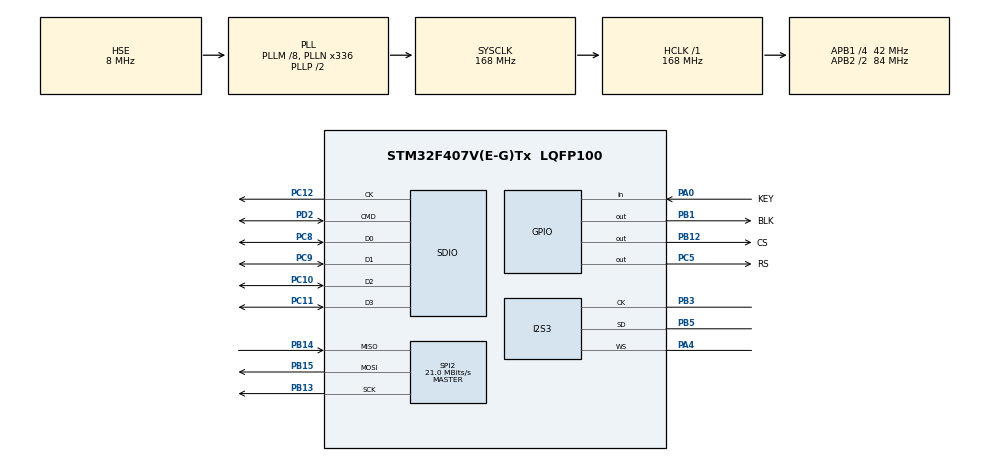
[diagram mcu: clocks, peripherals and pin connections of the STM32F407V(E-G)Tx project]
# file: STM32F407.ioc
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Dma.Request0=SDIO_RX
Dma.Request1=SDIO_TX
Dma.Request2=SPI2_RX
Dma.Request3=SPI2_TX
Dma.Request4=SPI3_TX
Dma.SDIO_RX.0.Direction=DMA_PERIPH_TO_MEMORY
Dma.SDIO_RX.0.FIFOMode=DMA_FIFOMODE_ENABLE
Dma.SDIO_RX.0.FIFOThreshold=DMA_FIFO_THRESHOLD_FULL
Dma.SDIO_RX.0.Instance=DMA2_Stream3
Dma.SDIO_RX.0.MemBurst=DMA_MBURST_INC4
Dma.SDIO_RX.0.MemDataAlignment=DMA_MDATAALIGN_WORD
Dma.SDIO_RX.0.MemInc=DMA_MINC_ENABLE
Dma.SDIO_RX.0.Mode=DMA_PFCTRL
Dma.SDIO_RX.0.PeriphBurst=DMA_PBURST_INC4
Dma.SDIO_RX.0.PeriphDataAlignment=DMA_PDATAALIGN_WORD
Dma.SDIO_RX.0.PeriphInc=DMA_PINC_DISABLE
Dma.SDIO_RX.0.Priority=DMA_PRIORITY_LOW
Dma.SDIO_TX.1.Direction=DMA_MEMORY_TO_PERIPH
Dma.SDIO_TX.1.FIFOMode=DMA_FIFOMODE_ENABLE
Dma.SDIO_TX.1.FIFOThreshold=DMA_FIFO_THRESHOLD_FULL
Dma.SDIO_TX.1.Instance=DMA2_Stream6
Dma.SDIO_TX.1.MemBurst=DMA_MBURST_INC4
Dma.SDIO_TX.1.MemDataAlignment=DMA_MDATAALIGN_WORD
Dma.SDIO_TX.1.MemInc=DMA_MINC_ENABLE
Dma.SDIO_TX.1.Mode=DMA_PFCTRL
Dma.SDIO_TX.1.PeriphBurst=DMA_PBURST_INC4
Dma.SDIO_TX.1.PeriphDataAlignment=DMA_PDATAALIGN_WORD
Dma.SDIO_TX.1.PeriphInc=DMA_PINC_DISABLE
Dma.SDIO_TX.1.Priority=DMA_PRIORITY_LOW
Dma.SPI2_RX.2.Direction=DMA_PERIPH_TO_MEMORY
Dma.SPI2_RX.2.FIFOMode=DMA_FIFOMODE_DISABLE
Dma.SPI2_RX.2.Instance=DMA1_Stream3
Dma.SPI2_RX.2.MemDataAlignment=DMA_MDATAALIGN_BYTE
Dma.SPI2_RX.2.MemInc=DMA_MINC_ENABLE
Dma.SPI2_RX.2.Mode=DMA_NORMAL
Dma.SPI2_RX.2.PeriphDataAlignment=DMA_PDATAALIGN_BYTE
Dma.SPI2_RX.2.PeriphInc=DMA_PINC_DISABLE
Dma.SPI2_RX.2.Priority=DMA_PRIORITY_LOW
Dma.SPI2_TX.3.Direction=DMA_MEMORY_TO_PERIPH
Dma.SPI2_TX.3.FIFOMode=DMA_FIFOMODE_DISABLE
Dma.SPI2_TX.3.Instance=DMA1_Stream4
Dma.SPI2_TX.3.MemDataAlignment=DMA_MDATAALIGN_BYTE
Dma.SPI2_TX.3.MemInc=DMA_MINC_ENABLE
Dma.SPI2_TX.3.Mode=DMA_NORMAL
Dma.SPI2_TX.3.PeriphDataAlignment=DMA_PDATAALIGN_BYTE
Dma.SPI2_TX.3.PeriphInc=DMA_PINC_DISABLE
Dma.SPI2_TX.3.Priority=DMA_PRIORITY_LOW
Dma.SPI3_TX.4.Direction=DMA_MEMORY_TO_PERIPH
Dma.SPI3_TX.4.FIFOMode=DMA_FIFOMODE_DISABLE
Dma.SPI3_TX.4.Instance=DMA1_Stream5
Dma.SPI3_TX.4.MemDataAlignment=DMA_MDATAALIGN_BYTE
Dma.SPI3_TX.4.MemInc=DMA_MINC_ENABLE
Dma.SPI3_TX.4.Mode=DMA_NORMAL
Dma.SPI3_TX.4.PeriphDataAlignment=DMA_PDATAALIGN_BYTE
Dma.SPI3_TX.4.PeriphInc=DMA_PINC_DISABLE
Dma.SPI3_TX.4.Priority=DMA_PRIORITY_LOW
FREERTOS.Tasks01=defaultTask,24,512,StartDefaultTask,Default,NULL,Dynamic,NULL,NULL
FREERTOS.configUSE_NEWLIB_REENTRANT=1
I2S3.AudioFreq=I2S_AUDIOFREQ_44K
I2S3.ErrorAudioFreq=0.67 %
I2S3.FullDuplexMode=I2S_FULLDUPLEXMODE_DISABLE
I2S3.Instance=SPI$Index
I2S3.RealAudioFreq=44.299 KHz
I2S3.VirtualMode=I2S_MODE_MASTER
Mcu.Family=STM32F4
Mcu.Name=STM32F407V(E-G)Tx
Mcu.Package=LQFP100
NVIC.DMA1_Stream3_IRQn=true\:5\:0\:false\:false\:true\:true\:false\:true\:true
NVIC.DMA1_Stream4_IRQn=true\:5\:0\:false\:false\:true\:true\:false\:true\:true
NVIC.DMA1_Stream5_IRQn=true\:5\:0\:false\:false\:true\:true\:false\:true\:true
NVIC.DMA2_Stream3_IRQn=true\:5\:0\:false\:false\:true\:true\:false\:true\:true
NVIC.DMA2_Stream6_IRQn=true\:5\:0\:false\:false\:true\:true\:false\:true\:true
NVIC.PriorityGroup=NVIC_PRIORITYGROUP_4
NVIC.SDIO_IRQn=true\:5\:0\:false\:false\:true\:true\:true\:true\:true
NVIC.SPI2_IRQn=true\:5\:0\:false\:false\:true\:true\:true\:true\:true
NVIC.TIM1_UP_TIM10_IRQn=true\:15\:0\:false\:false\:true\:false\:false\:true\:true
NVIC.TimeBase=TIM1_UP_TIM10_IRQn
NVIC.TimeBaseIP=TIM1
PA0-WKUP.GPIO_Label=KEY
PA0-WKUP.GPIO_PuPd=GPIO_PULLDOWN
PA0-WKUP.Signal=GPIO_Input
PA4.GPIO_Speed=GPIO_SPEED_FREQ_VERY_HIGH
PA4.Mode=Half_Duplex_Master
PA4.Signal=I2S3_WS
PB1.GPIO_Label=BLK
PB1.Signal=GPIO_Output
PB12.GPIO_Label=CS
PB12.Signal=GPIO_Output
PB13.Mode=Full_Duplex_Master
PB13.Signal=SPI2_SCK
PB14.GPIO_PuPd=GPIO_PULLUP
PB14.Mode=Full_Duplex_Master
PB14.Signal=SPI2_MISO
PB15.Mode=Full_Duplex_Master
PB15.Signal=SPI2_MOSI
PB3.GPIO_Speed=GPIO_SPEED_FREQ_VERY_HIGH
PB3.Mode=Half_Duplex_Master
PB3.Signal=I2S3_CK
PB5.GPIO_Speed=GPIO_SPEED_FREQ_VERY_HIGH
PB5.Mode=Half_Duplex_Master
PB5.Signal=I2S3_SD
PC10.Mode=SD_4_bits_Wide_bus
PC10.Signal=SDIO_D2
PC11.Mode=SD_4_bits_Wide_bus
PC11.Signal=SDIO_D3
PC12.Mode=SD_4_bits_Wide_bus
PC12.Signal=SDIO_CK
PC14-OSC32_IN.Mode=LSE-External-Oscillator
PC14-OSC32_IN.Signal=RCC_OSC32_IN
PC15-OSC32_OUT.Mode=LSE-External-Oscillator
PC15-OSC32_OUT.Signal=RCC_OSC32_OUT
PC5.GPIO_Label=RS
PC5.Signal=GPIO_Output
PC8.Mode=SD_4_bits_Wide_bus
PC8.Signal=SDIO_D0
PC9.Mode=SD_4_bits_Wide_bus
PC9.Signal=SDIO_D1
PD2.Mode=SD_4_bits_Wide_bus
PD2.Signal=SDIO_CMD
PH0-OSC_IN.Mode=HSE-External-Oscillator
PH0-OSC_IN.Signal=RCC_OSC_IN
PH1-OSC_OUT.Mode=HSE-External-Oscillator
PH1-OSC_OUT.Signal=RCC_OSC_OUT
ProjectManager.HeapSize=0x200
ProjectManager.StackSize=0x400
ProjectManager.TargetToolchain=STM32CubeIDE
RCC.48MHZClocksFreq_Value=48000000
RCC.AHBFreq_Value=168000000
RCC.APB1CLKDivider=RCC_HCLK_DIV4
RCC.APB1Freq_Value=42000000
RCC.APB1TimFreq_Value=84000000
RCC.APB2CLKDivider=RCC_HCLK_DIV2
RCC.APB2Freq_Value=84000000
RCC.APB2TimFreq_Value=168000000
RCC.CortexFreq_Value=168000000
RCC.HCLKFreq_Value=168000000
RCC.HSE_VALUE=8000000
RCC.HSI_VALUE=16000000
RCC.PLLI2SN=258
RCC.PLLI2SR=7
RCC.PLLM=8
RCC.PLLN=336
RCC.PLLQ=7
RCC.PLLSourceVirtual=RCC_PLLSOURCE_HSE
RCC.SYSCLKFreq_VALUE=168000000
RCC.SYSCLKSource=RCC_SYSCLKSOURCE_PLLCLK
RCC.VCOOutputFreq_Value=336000000
SDIO.ClockBypass=SDIO_CLOCK_BYPASS_DISABLE
SDIO.ClockDiv=0
SDIO.ClockPowerSave=SDIO_CLOCK_POWER_SAVE_DISABLE
SDIO.HardwareFlowControl=SDIO_HARDWARE_FLOW_CONTROL_DISABLE
SPI2.BaudRatePrescaler=SPI_BAUDRATEPRESCALER_2
SPI2.CalculateBaudRate=21.0 MBits/s
SPI2.DataSize=SPI_DATASIZE_8BIT
SPI2.Direction=SPI_DIRECTION_2LINES
SPI2.Mode=SPI_MODE_MASTER
SPI2.VirtualType=VM_MASTER
VP_FATFS_VS_SDIO.Mode=SDIO
VP_FREERTOS_VS_CMSIS_V2.Mode=CMSIS_V2
VP_SYS_VS_tim1.Mode=TIM1
board=custom

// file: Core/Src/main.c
/* USER CODE BEGIN Header */
/**
  ******************************************************************************
  * @file           : main.c
  * @brief          : Main program body
  ******************************************************************************
  * @attention
  *
  * Copyright (c) 2026 STMicroelectronics.
  * All rights reserved.
  *
  * This software is licensed under terms that can be found in the LICENSE file
  * in the root directory of this software component.
  * If no LICENSE file comes with this software, it is provided AS-IS.
  *
  ******************************************************************************
  */
/* USER CODE END Header */
#include "main.h"
#include "cmsis_os.h"
#include "dma.h"
#include "fatfs.h"
#include "i2s.h"
#include "sdio.h"
#include "spi.h"
#include "gpio.h"

void SystemClock_Config(void);
void MX_FREERTOS_Init(void);

int main(void)
{

  /* MCU Configuration--------------------------------------------------------*/

  /* Reset of all peripherals, Initializes the Flash interface and the Systick. */
  HAL_Init();

  /* Configure the system clock */
  SystemClock_Config();

  /* Initialize all configured peripherals */
  MX_GPIO_Init();
  MX_DMA_Init();
  MX_SDIO_SD_Init();
  MX_FATFS_Init();
  MX_SPI2_Init();
  MX_I2S3_Init();

  /* Init scheduler */
  osKernelInitialize();  /* Call init function for freertos objects (in cmsis_os2.c) */
  MX_FREERTOS_Init();

  /* Start scheduler */
  osKernelStart();

  /* We should never get here as control is now taken by the scheduler */

  /* Infinite loop */
  while (1)
  {

  }
}

void SystemClock_Config(void)
{
  RCC_OscInitTypeDef RCC_OscInitStruct = {0};
  RCC_ClkInitTypeDef RCC_ClkInitStruct = {0};

  /** Configure the main internal regulator output voltage
  */
  __HAL_RCC_PWR_CLK_ENABLE();
  __HAL_PWR_VOLTAGESCALING_CONFIG(PWR_REGULATOR_VOLTAGE_SCALE1);

  /** Initializes the RCC Oscillators according to the specified parameters
  * in the RCC_OscInitTypeDef structure.
  */
  RCC_OscInitStruct.OscillatorType = RCC_OSCILLATORTYPE_HSE;
  RCC_OscInitStruct.HSEState = RCC_HSE_ON;
  RCC_OscInitStruct.PLL.PLLState = RCC_PLL_ON;
  RCC_OscInitStruct.PLL.PLLSource = RCC_PLLSOURCE_HSE;
  RCC_OscInitStruct.PLL.PLLM = 8;
  RCC_OscInitStruct.PLL.PLLN = 336;
  RCC_OscInitStruct.PLL.PLLP = RCC_PLLP_DIV2;
  RCC_OscInitStruct.PLL.PLLQ = 7;
  if (HAL_RCC_OscConfig(&RCC_OscInitStruct) != HAL_OK)
  {
    Error_Handler();
  }

  /** Initializes the CPU, AHB and APB buses clocks
  */
  RCC_ClkInitStruct.ClockType = RCC_CLOCKTYPE_HCLK|RCC_CLOCKTYPE_SYSCLK
                              |RCC_CLOCKTYPE_PCLK1|RCC_CLOCKTYPE_PCLK2;
  RCC_ClkInitStruct.SYSCLKSource = RCC_SYSCLKSOURCE_PLLCLK;
  RCC_ClkInitStruct.AHBCLKDivider = RCC_SYSCLK_DIV1;
  RCC_ClkInitStruct.APB1CLKDivider = RCC_HCLK_DIV4;
  RCC_ClkInitStruct.APB2CLKDivider = RCC_HCLK_DIV2;

  if (HAL_RCC_ClockConfig(&RCC_ClkInitStruct, FLASH_LATENCY_5) != HAL_OK)
  {
    Error_Handler();
  }
}

void HAL_TIM_PeriodElapsedCallback(TIM_HandleTypeDef *htim)
{
  if (htim->Instance == TIM1)
  {
    HAL_IncTick();
  }
}

void Error_Handler(void)
{
  __disable_irq();
  while (1)
  {
  }
}

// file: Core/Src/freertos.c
/* USER CODE BEGIN Header */
/**
  ******************************************************************************
  * File Name          : freertos.c
  * Description        : Code for freertos applications
  ******************************************************************************
  * @attention
  *
  * Copyright (c) 2026 STMicroelectronics.
  * All rights reserved.
  *
  * This software is licensed under terms that can be found in the LICENSE file
  * in the root directory of this software component.
  * If no LICENSE file comes with this software, it is provided AS-IS.
  *
  ******************************************************************************
  */
/* USER CODE END Header */

#include "FreeRTOS.h"
#include "task.h"
#include "main.h"
#include "cmsis_os.h"

/* USER CODE BEGIN Includes */
#include "file_browser.h"
/* USER CODE END Includes */

/* Definitions for defaultTask */
osThreadId_t defaultTaskHandle;
const osThreadAttr_t defaultTask_attributes = {
  .name = "defaultTask",
  .stack_size = 512 * 4,
  .priority = (osPriority_t) osPriorityNormal,
};

void StartDefaultTask(void *argument);

void MX_FREERTOS_Init(void); /* (MISRA C 2004 rule 8.1) */

void MX_FREERTOS_Init(void) {

  /* Create the thread(s) */
  /* creation of defaultTask */
  defaultTaskHandle = osThreadNew(StartDefaultTask, NULL, &defaultTask_attributes);

}

void StartDefaultTask(void *argument)
{
  /* USER CODE BEGIN StartDefaultTask */
  FB_Init();
  FB_Run();
  /* USER CODE END StartDefaultTask */
}
